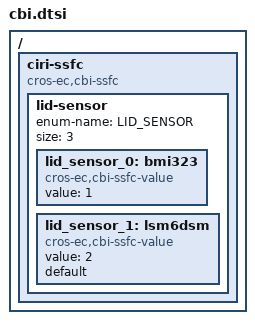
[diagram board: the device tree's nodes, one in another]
/* Copyright 2024 The ChromiumOS Authors
 * Use of this source code is governed by a BSD-style license that can be
 * found in the LICENSE file.
 */

/ {
	/* Ciri-specific ssfc fields. */
	ciri-ssfc {
		compatible = "cros-ec,cbi-ssfc";

		/* SSFC field to identify LID motion sensor. */
		lid-sensor {
			enum-name = "LID_SENSOR";
			size = <3>;

			lid_sensor_0: bmi323 {
				compatible = "cros-ec,cbi-ssfc-value";
				status = "okay";
				value = <1>;
			};
			lid_sensor_1: lsm6dsm {
				compatible = "cros-ec,cbi-ssfc-value";
				status = "okay";
				value = <2>;
				default;
			};
		};
	};
};
